# STM32C593xx register map
File version: 1.0
Registers are 32-bit, read-write, reset 0x0 unless marked. A register's access mark holds for its fields unless they carry their own. Offsets are from the block's base; [hi:lo] are bit positions; {n}, {i} and the like mark numbered series.

## HASH — Hash processor (HASH)
Base 0x420C0400
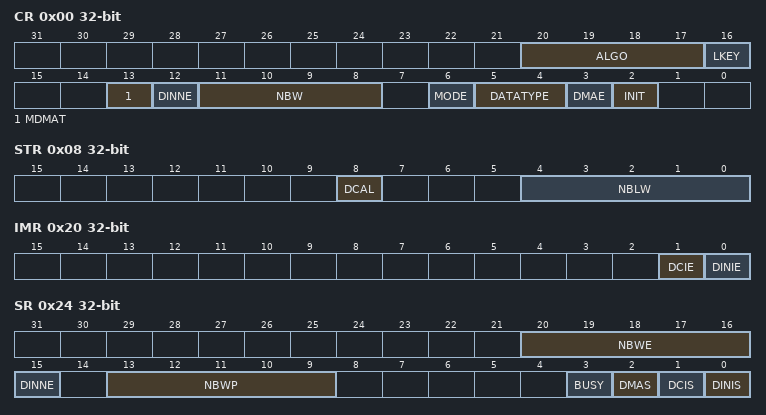
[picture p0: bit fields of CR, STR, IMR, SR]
0x00 CR — HASH control register
  [20:17] ALGO — Algorithm selection
  [16] LKEY — Long key selection
  [13] MDMAT — Multiple DMA transfers
  [12] DINNE — DIN not empty
  [11:8] NBW — Number of words already pushed
  [6] MODE — Mode selection
  [5:4] DATATYPE — Data type selection
  [3] DMAE — DMA enable
  [2] INIT — Initialize message digest calculation
0x04 DIN — HASH data input register
  [31:0] DATAIN — Data input
0x08 STR — HASH start register
  [8] DCAL — Digest calculation
  [4:0] NBLW — Number of valid bits in the last word
{0xC+4i} HRA{i} ro (i=0..4) — HASH digest registers
0x20 IMR — HASH interrupt enable register
  [1] DCIE — Digest calculation completion interrupt enable
  [0] DINIE — Data input interrupt enable
0x24 SR — HASH status register
  [20:16] NBWE — Number of words expected
  [15] DINNE — DIN not empty
  [13:9] NBWP — Number of words already pushed
  [3] BUSY — Busy bit
  [2] DMAS — DMA Status
  [1] DCIS — Digest calculation completion interrupt status
  [0] DINIS — Data input interrupt status
{0xF8+4i} CSR{i} (i=0..102) — HASH context swap register
  [31:0] CS — Context swap x
{0x310+4i} HR{i} ro (i=0..15) — HASH digest register
  [31:0] H — Hash data x

## RNG — True random number generator (RNG)
Base 0x420C0800
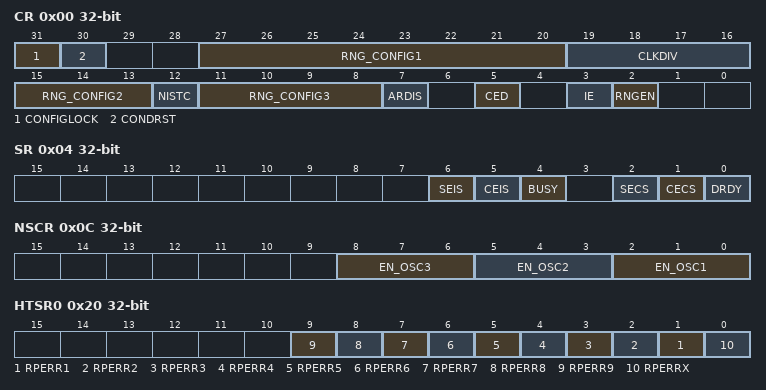
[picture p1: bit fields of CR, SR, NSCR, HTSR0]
0x00 CR — RNG control register
  [31] CONFIGLOCK — RNG configuration lock
  [30] CONDRST — Conditioning soft reset
  [27:20] RNG_CONFIG1 — RNG configuration 1
  [19:16] CLKDIV — Clock divider factor
  [15:13] RNG_CONFIG2 — RNG configuration 2
  [12] NISTC — NIST custom
  [11:8] RNG_CONFIG3 — RNG configuration 3
  [7] ARDIS — Auto reset disable
  [5] CED — Clock error detection
  [3] IE — Interrupt enable
  [2] RNGEN — True random number generator enable
0x04 SR — RNG status register
  [6] SEIS — Seed error interrupt status
  [5] CEIS — Clock error interrupt status
  [4] BUSY
  [2] SECS — Seed error current status
  [1] CECS — Clock error current status
  [0] DRDY — Data ready
0x08 DR ro — RNG data register
  [31:0] RNDATA — Random data
0x0C NSCR — RNG noise source control register
  [8:6] EN_OSC3, [5:3] EN_OSC2, [2:0] EN_OSC1
{0x10+4i} HTCR{i} (i=0..3) — RNG health test configuration register
  [31:0] HTCFG — health test configuration
0x20 HTSR0 ro — RNG health test status register
  [n] RPERR{n} (n=1..9) — Repetitive error for oscillator i
  [0] RPERRX — Repetitive error after the XOR
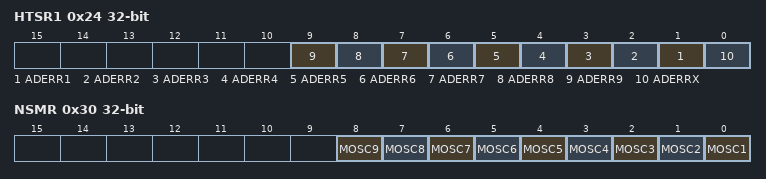
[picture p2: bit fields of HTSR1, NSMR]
0x24 HTSR1 ro — RNG health test status register
  [n] ADERR{n} (n=1..9) — Adaptative error for oscillator i
  [0] ADERRX — Adaptative error after the XOR
0x30 NSMR — RNG health test status register
  [n-1] MOSC{n} (n=1..9) — Mask oscillator i

## PKA — Public key accelerator (PKA)
Base 0x420C2000
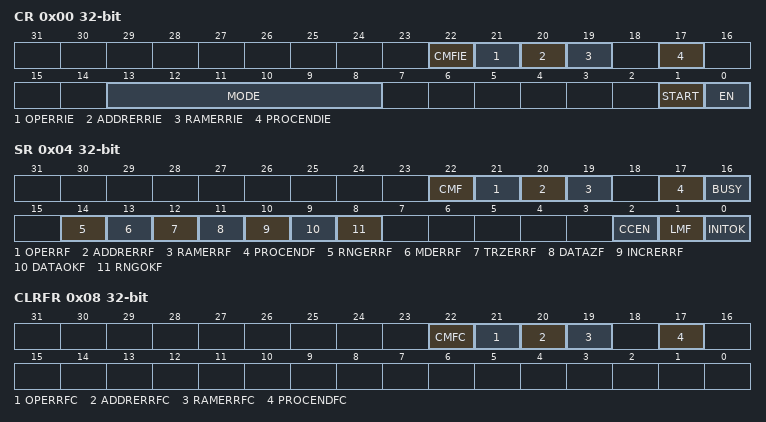
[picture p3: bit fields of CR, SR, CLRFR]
0x00 CR — PKA control register
  [22] CMFIE — Chaining mode flags interrupt enable
  [21] OPERRIE — Operation error interrupt enable
  [20] ADDRERRIE — Address error interrupt enable
  [19] RAMERRIE — RAM error interrupt enable
  [17] PROCENDIE — End of operation interrupt enable
  [13:8] MODE — PKA operation code
  [1] START — start the operation
  [0] EN — PKA enable
0x04 SR ro — PKA status register
  [22] CMF — Chaining mode flags
  [21] OPERRF — Operation error flag
  [20] ADDRERRF — Address error flag
  [19] RAMERRF — PKA RAM error flag
  [17] PROCENDF — PKA end of operation flag
  [16] BUSY — Busy flag
  [14] RNGERRF — RNG error flag
  [13] MDERRF — Mode error flag
  [12] TRZERRF — Trailing 0s error flag
  [11] DATAZF — Data 0-ed error flag
  [10] INCRERRF — Increment error flag
  [9] DATAOKF — Data OK flag
  [8] RNGOKF — RNG OK flag
  [2] CCEN — Coupling and chaining mode enable
  [1] LMF — Limited mode flag
  [0] INITOK — PKA initialization OK
0x08 CLRFR — PKA clear flag register
  [22] CMFC — Clear chaining mode flag
  [21] OPERRFC — Clear operation error flag
  [20] ADDRERRFC — Clear address error flag
  [19] RAMERRFC — Clear PKA RAM error flag
  [17] PROCENDFC — Clear PKA end of operation flag
{0x400+i} RAM[{i}] (i=0..5335) 8-bit
